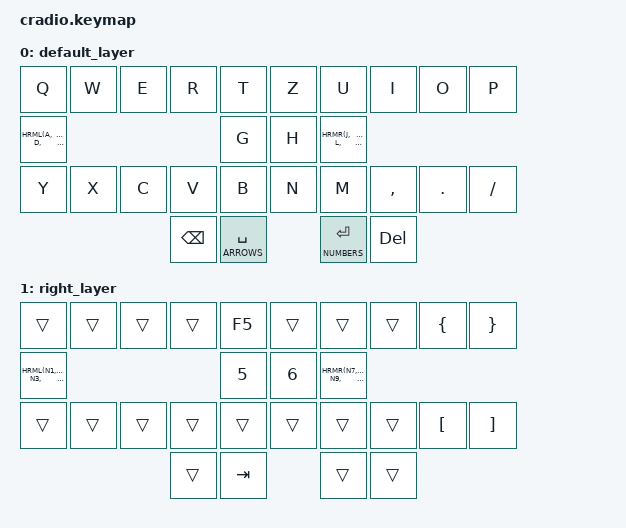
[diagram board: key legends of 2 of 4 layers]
// Copyright (c) 2022 The ZMK Contributors
// SPDX-License-Identifier: MIT

#include <behaviors.dtsi>
#include <dt-bindings/zmk/keys.h>
#include <dt-bindings/zmk/bt.h>

// Home row mods macro
#define HRML(k1,k2,k3,k4) &ht LWIN k1  &ht LALT k2  &ht LCTRL k3  &ht LSHFT k4
#define HRMR(k1,k2,k3,k4) &ht RSHFT k1  &ht RCTRL k2  &ht RALT k3  &ht RWIN k4

#define DEFAULT 0
#define ARROWS 2
#define NUMBERS 1
#define BLUET 3

/ {
    behaviors {
        ht: hold_tap {
            compatible = "zmk,behavior-hold-tap";
            #binding-cells = <2>;
            flavor = "tap-preferred";
            tapping-term-ms = <220>;
            quick-tap-ms = <150>;
            require-prior-idle-ms = <100>;
            bindings = <&kp>, <&kp>;
        };
    };

    conditional_layers {
        compatible = "zmk,conditional-layers";
        tri_layer {
            if-layers = <1 2>;
            then-layer = <3>;
        };
    };

    keymap {
        compatible = "zmk,keymap";
        default_layer {
            bindings = <
        //╭──────────┬──────────┬──────────┬──────────┬──────────╮   ╭──────────┬──────────┬──────────┬──────────┬──────────╮
        //│  Q       │  W       │  E       │  R       │  T       │   │  Z       │  U       │  I       │  O       │  P       │
            &kp Q      &kp W      &kp E      &kp R      &kp T          &kp Z      &kp U      &kp I      &kp O      &kp P
        //├──────────┼──────────┼──────────┼──────────┼──────────┤   ├──────────┼──────────┼──────────┼──────────┼──────────┤
        //│  A       │  S       │  D       │  F       │  G       │   │  H       │  J       │  K       │  L       │   ' "    │
            HRML(A,        S,         D,         F)     &kp G          &kp H      HRMR(J,        K,         L,       SQT)
        //├──────────┼──────────┼──────────┼──────────┼──────────┤   ├──────────┼──────────┼──────────┼──────────┼──────────┤
        //│  Y       │  X       │  C       │  V       │  B       │   │  N       │  M       │ , <      │ . >      │ / ?      │
            &kp Y      &kp X      &kp C      &kp V      &kp B          &kp N      &kp M      &kp COMMA  &kp DOT    &kp FSLH
        //╰──────────┴──────────┴──────────┼──────────┼──────────┤   ├──────────┼──────────┼──────────┴──────────┴──────────╯
                                           &kp BSPC &lt ARROWS SPACE &lt NUMBERS ENTER  &kp DEL
        //                                 ╰──────────┴──────────╯   ╰──────────┴──────────╯
            >;
        };

        right_layer { // layer 1
            bindings = <
        //╭──────────┬──────────┬──────────┬──────────┬──────────╮   ╭──────────┬──────────┬──────────┬──────────┬──────────╮
        //│          │          │          │          │    F5    │   │          │          │          │    {     │    }     │
            &trans     &trans     &trans     &trans     &kp F5         &trans     &trans     &trans     &kp LBRC  &kp RBRC
        //├──────────┼──────────┼──────────┼──────────┼──────────┤   ├──────────┼──────────┼──────────┼──────────┼──────────┤
        //│   1 !    │   2 @    │   3 #    │   4 $    │   5 %    │   │   6 ^    │   7 &    │   8 *    │   9 (    │   0 )    │
            HRML(N1,     N2,        N3,        N4)      &kp N5         &kp N6      HRMR(N7,    N8,        N9,        N0) 
        //├──────────┼──────────┼──────────┼──────────┼──────────┤   ├──────────┼──────────┼──────────┼──────────┼──────────┤
        //│          │          │          │          │          │   │          │          │          │    [     │     ]    │
            &trans     &trans     &trans     &trans     &trans         &trans     &trans     &trans     &kp LBKT   &kp RBKT
        //╰──────────┴──────────┴──────────┼──────────┼──────────┤   ├──────────┼──────────┼──────────┴──────────┴──────────╯
                                             &trans     &kp TAB        &trans     &trans
        //                                 ╰──────────┴──────────╯   ╰──────────┴──────────╯
            >;
        };

        left_layer { // layer 2
            bindings = <
        //╭──────────┬──────────┬──────────┬──────────┬──────────╮   ╭──────────┬──────────┬──────────┬──────────┬──────────╮
        //│          │          │          │          │          │   │   pgup   │   HOME   │    UP    │   END    │   \ |    │
            &trans     &trans      &trans     &trans     &trans        &kp PG_UP  &kp HOME    &kp UP    &kp END   &kp BSLH
        //├──────────┼──────────┼──────────┼──────────┼──────────┤   ├──────────┼──────────┼──────────┼──────────┼──────────┤
        //│   ` ~    │   ALT    │   CTRL   │  SHIFT   │          │   │   pgdn   │   LEFT   │   DOWN   │  RIGHT   │   ; :    │
           HRML(GRAVE,   LALT,     LCTRL,    LSHIFT)     &trans       &kp PG_DN  &kp LEFT  &kp DOWN     &kp RIGHT   &kp SEMI
        //├──────────┼──────────┼──────────┼──────────┼──────────┤   ├──────────┼──────────┼──────────┼──────────┼──────────┤
        //│          │          │          │          │          │   │          │          │          │          │   - _    │
            &trans     &trans     &trans     &trans     &trans         &trans      &trans     &trans     &trans    &kp MINUS
        //╰──────────┴──────────┴──────────┼──────────┼──────────┤   ├──────────┼──────────┼──────────┴──────────┴──────────╯
                                             &trans      &trans        &kp ESC    &trans
        //                                 ╰──────────┴──────────╯   ╰──────────┴──────────╯
            >;
        };

        configure_layer { // layer 3
            bindings = <
        //╭──────────┬──────────┬──────────┬──────────┬──────────╮   ╭──────────┬──────────┬──────────┬──────────┬──────────╮
        //│          │          │          │          │          │   │          │          │          │          │          │
            &trans     &trans      &trans     &trans     &trans        &trans      &trans     &trans     &trans     &trans
        //├──────────┼──────────┼──────────┼──────────┼──────────┤   ├──────────┼──────────┼──────────┼──────────┼──────────┤
        //│   BT0    │   BT1    │   BT2    │   BT3    │   BT4    │   │          │          │          │          │          │
             &trans     &trans     &trans     &trans     &trans         &trans     &trans     &trans     &trans     &trans
        //├──────────┼──────────┼──────────┼──────────┼──────────┤   ├──────────┼──────────┼──────────┼──────────┼──────────┤
        //│          │          │          │          │          │   │          │          │          │          │          │
            &trans     &trans     &trans     &trans     &trans         &trans      &trans     &trans     &trans     &trans
        //╰──────────┴──────────┴──────────┼──────────┼──────────┤   ├──────────┼──────────┼──────────┴──────────┴──────────╯
                                             &trans      &trans        &trans      &trans
        //                                 ╰──────────┴──────────╯   ╰──────────┴──────────╯
            >;
        };
    };
};
